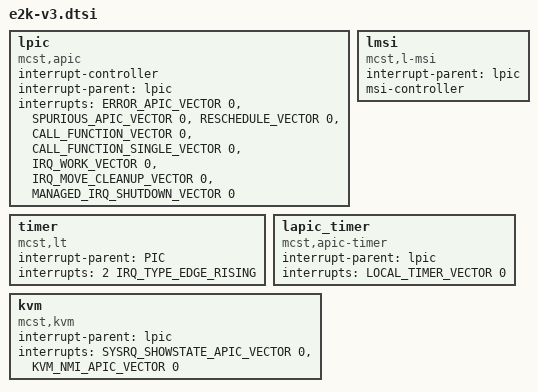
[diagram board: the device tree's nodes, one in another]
/*
 * SPDX-License-Identifier: GPL-2.0
 * Copyright (c) 2023 MCST
 */

#include <dt-bindings/interrupt-controller/irq.h>
#include "apic-vectors.h"
#include "e2k-macro.dtsi"

	lpic: lpic {
		compatible = "mcst,apic";
		interrupt-controller;

		#interrupt-cells = <2>;

		interrupt-parent = <&lpic>;
		interrupts =
			<ERROR_APIC_VECTOR		0>,
			<SPURIOUS_APIC_VECTOR		0>,
			<RESCHEDULE_VECTOR		0>,
			<CALL_FUNCTION_VECTOR		0>,
			<CALL_FUNCTION_SINGLE_VECTOR	0>,
			<IRQ_WORK_VECTOR		0>,
			<IRQ_MOVE_CLEANUP_VECTOR	0>,
			<MANAGED_IRQ_SHUTDOWN_VECTOR	0>;
			interrupt-names = "ERR Error interrupts",
				"SPU Spurious interrupts",
				"RES Rescheduling interrupts",
				"CAL Function call interrupts",
				"CAL Function single call interrupts",
				"IWI IRQ work interrupts",
				"IMI IRQ move cleanup interrupts",
				"MSV managed irq shutdown vector";
	};
	lmsi: lmsi {
		compatible = "mcst,l-msi";
		interrupt-parent = <&lpic>;
		msi-controller;
	};
	timer {
		compatible = "mcst,lt";
		interrupt-parent = <&PIC>;
		interrupts = <2 IRQ_TYPE_EDGE_RISING>;
	};
	lapic_timer {
		compatible = "mcst,apic-timer";
		interrupt-parent = <&lpic>;
		interrupts = <LOCAL_TIMER_VECTOR 0>;
	};
	kvm {
		compatible = "mcst,kvm";
		interrupt-parent = <&lpic>;
		interrupts =
			<SYSRQ_SHOWSTATE_APIC_VECTOR	0>,
			<KVM_NMI_APIC_VECTOR		0>;
		interrupt-names =
			"KVM SysRq showstate",
			"KVM NMI";
	};
